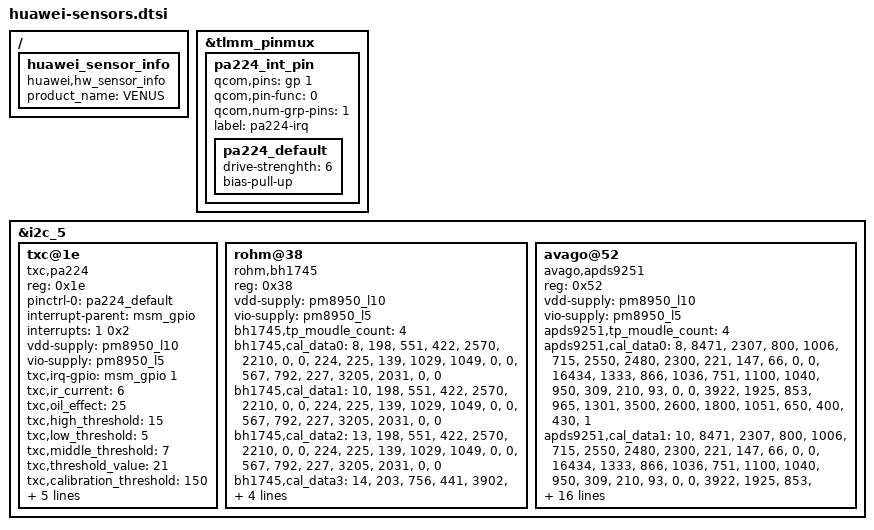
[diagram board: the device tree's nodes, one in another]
/*use fromdos convert file format to linux*/
/* Copyright (c) 2013 The Linux Foundation. All rights reserved.
 *
 * This program is free software; you can redistribute it and/or modify
 * it under the terms of the GNU General Public License version 2 and
 * only version 2 as published by the Free Software Foundation.
 *
 * This program is distributed in the hope that it will be useful,
 * but WITHOUT ANY WARRANTY; without even the implied warranty of
 * MERCHANTABILITY or FITNESS FOR A PARTICULAR PURPOSE.  See the
 * GNU General Public License for more details.
 */
&tlmm_pinmux {
	pa224_int_pin {
		qcom,pins = <&gp 1>;
		qcom,pin-func = <0>;
		qcom,num-grp-pins = <1>;
		label = "pa224-irq";
		pa224_default: pa224_default {
			drive-strenghth = <6>;
			bias-pull-up;
		};
	};
};

&i2c_5{
	txc@1e {
		compatible = "txc,pa224";
		reg = <0x1e>;
		pinctrl-names = "default";
		pinctrl-0 = <&pa224_default>;
		interrupt-parent = <&msm_gpio>;
		interrupts = <1 0x2>;
		vdd-supply = <&pm8950_l10>;
		vio-supply = <&pm8950_l5>;
		txc,irq-gpio = <&msm_gpio 1 0x2>;
		/*IR CURRENT 10MA*/
		txc,ir_current = <6>;
		txc,oil_effect = <25>;
		txc,high_threshold = <15>;
		txc,low_threshold = <5>;
		txc,middle_threshold = <7>;
		txc,threshold_value = <21>;
		txc,calibration_threshold = <150>;
		txc,ps_window = <80>;
		txc,ps_wave = <40>;
		txc,ps_defalt_crosstalk = <50>;
		txc,i2c-scl-gpio = <&msm_gpio 19 0x0>;
		txc,i2c-sda-gpio = <&msm_gpio 18 0x0>;
	};
	rohm@38 {
		compatible = "rohm,bh1745";
		reg = <0x38>;
		vdd-supply = <&pm8950_l10>;
		vio-supply = <&pm8950_l5>;
		bh1745,tp_moudle_count = <4>;
		/*[module_id] [golden judge] r[0] r[1] g[0] g[1] b[0] b[1]*/
		bh1745,cal_data0 =  "8","198","551","422","2570","2210","0","0",
		/*[white judge] r[0] r[1] g[0] g[1] b[0] b[1]*/
		"224","225","139","1029","1049","0","0",
		/*[black judge] r[0] r[1] g[0] g[1] b[0] b[1]*/
		"567","792","227","3205","2031","0","0";
		/*[module_id] [golden judge] r[0] r[1] g[0] g[1] b[0] b[1]*/
		bh1745,cal_data1 =  "10","198","551","422","2570","2210","0","0",

		/*[white judge] r[0] r[1] g[0] g[1] b[0] b[1]*/
		"224","225","139","1029","1049","0","0",
		/*[black judge] r[0] r[1] g[0] g[1] b[0] b[1]*/
		"567","792","227","3205","2031","0","0";
		/*[module_id] [golden judge] r[0] r[1] g[0] g[1] b[0] b[1]*/
		bh1745,cal_data2 = "13","198","551","422","2570","2210","0","0",
		/*[white judge] r[0] r[1] g[0] g[1] b[0] b[1]*/
		"224","225","139","1029","1049","0","0",
		/*[black judge] r[0] r[1] g[0] g[1] b[0] b[1]*/
		"567","792","227","3205","2031","0","0";
		/*[module_id] [golden judge] r[0] r[1] g[0] g[1] b[0] b[1]*/
		bh1745,cal_data3 = "14","203","756","441","3902","3621","0","0",
		/*[white judge] r[0] r[1] g[0] g[1] b[0] b[1]*/
		"236","293","161","1401","1410","0","0",
		/*[black judge] r[0] r[1] g[0] g[1] b[0] b[1]*/
		"636","610","126","3121","2131","0","0";
		bh1745,i2c-scl-gpio = <&msm_gpio 19 0x0>;
		bh1745,i2c-sda-gpio = <&msm_gpio 18 0x0>;
	};
	avago@52 {
		compatible = "avago,apds9251";
		reg = <0x52>;
		vdd-supply = <&pm8950_l10>;
		vio-supply = <&pm8950_l5>;
		apds9251,tp_moudle_count = <4>;
		/*[module_id] [CCT_M] [CCT_N] [H] [A] [D] [LUX_P] [LUX_Q] [LUX_R] [cofficient0] [cofficient1] [cofficient2] [cofficient3] [lux_mix]*/
		apds9251,cal_data0 = "8","8471","2307","800","1006","715","2550","2480","2300","221","147","66","0","0",
		/*[CCT_M] [CCT_N] [H] [A] [D] [LUX_P] [LUX_Q] [LUX_R] [cofficient0] [cofficient1] [cofficient2] [cofficient3] [lux_mix]*/
		"16434","1333","866","1036","751","1100","1040","950","309","210","93","0","0",
		/*[CCT_M] [CCT_N] [H] [A] [D] [LUX_P] [LUX_Q] [LUX_R] [cofficient0] [cofficient1] [cofficient2] [cofficient3] [lux_mix]*/
		"3922","1925","853","965","1301","3500","2600","1800","1051","650","400","430","1";
		/*[module_id] [CCT_M] [CCT_N] [H] [A] [D] [LUX_P] [LUX_Q] [LUX_R] [cofficient0] [cofficient1] [cofficient2] [cofficient3] [lux_mix]*/
		apds9251,cal_data1 = "10","8471","2307","800","1006","715","2550","2480","2300","221","147","66","0","0",
		/*[CCT_M] [CCT_N] [H] [A] [D] [LUX_P] [LUX_Q] [LUX_R] [cofficient0] [cofficient1] [cofficient2] [cofficient3] [lux_mix]*/
		"16434","1333","866","1036","751","1100","1040","950","309","210","93","0","0",
		/*[CCT_M] [CCT_N] [H] [A] [D] [LUX_P] [LUX_Q] [LUX_R] [cofficient0] [cofficient1] [cofficient2] [cofficient3] [lux_mix]*/
		"3922","1925","853","965","1301","3500","2600","1800","1051","650","400","430","1";
		/*[module_id] [CCT_M] [CCT_N] [H] [A] [D] [LUX_P] [LUX_Q] [LUX_R] [cofficient0] [cofficient1] [cofficient2] [cofficient3] [lux_mix]*/
		apds9251,cal_data2 ="13","8471","2307","800","1006","715","2550","2480","2300","221","147","66","0","0",
		/*[CCT_M] [CCT_N] [H] [A] [D] [LUX_P] [LUX_Q] [LUX_R] [cofficient0] [cofficient1] [cofficient2] [cofficient3] [lux_mix]*/
		"16434","1333","866","1036","751","1100","1040","950","309","210","93","0","0",
		/*[CCT_M] [CCT_N] [H] [A] [D] [LUX_P] [LUX_Q] [LUX_R] [cofficient0] [cofficient1] [cofficient2] [cofficient3] [lux_mix]*/
		"3922","1925","853","965","1301","3500","2600","1800","1051","650","400","430","1";
		/*[module_id] [CCT_M] [CCT_N] [H] [A] [D] [LUX_P] [LUX_Q] [LUX_R] [cofficient0] [cofficient1] [cofficient2] [cofficient3] [lux_mix]*/
		apds9251,cal_data3 ="14","10079","1804","806","930","1160","3137","3050","2694","9000","156","69","0","0",
		/*[CCT_M] [CCT_N] [H] [A] [D] [LUX_P] [LUX_Q] [LUX_R] [cofficient0] [cofficient1] [cofficient2] [cofficient3] [lux_mix]*/
		"6240","1954","844","940","1218","1239","1288","1147","294","217","92","0","0",
		/*[CCT_M] [CCT_N] [H] [A] [D] [LUX_P] [LUX_Q] [LUX_R] [cofficient0] [cofficient1] [cofficient2] [cofficient3] [lux_mix]*/
		"3711","798","1392","1639","1778","2859","1369","933","9000","912","655","403","1";
		apds9251,i2c-scl-gpio = <&msm_gpio 19 0x0>;
		apds9251,i2c-sda-gpio = <&msm_gpio 18 0x0>;
	};
};

 / {
	huawei_sensor_info {
		compatible = "huawei,hw_sensor_info";
		product_name = "VENUS";
	};
};
